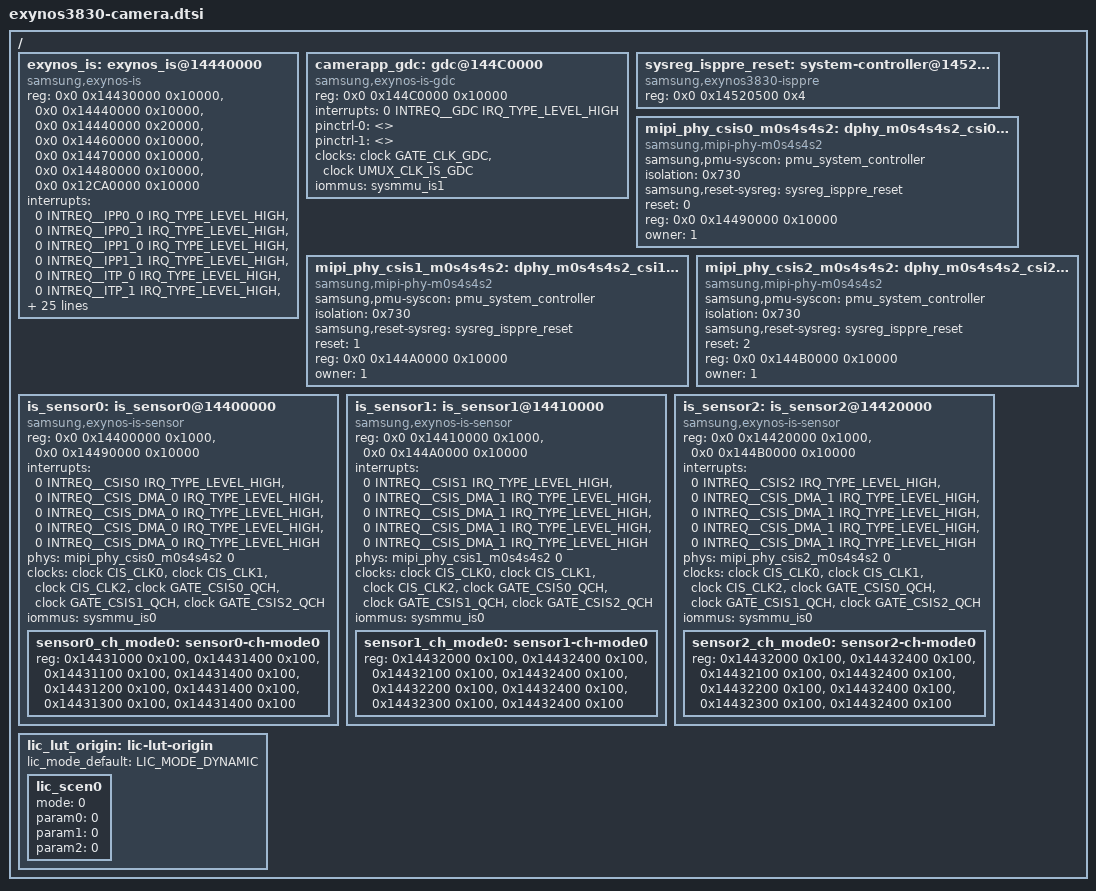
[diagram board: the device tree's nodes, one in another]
/*
 * SAMSUNG EXYNOS9630 SoC camera device tree source
 *
 * Copyright (c) 2019 Samsung Electronics Co., Ltd.
 *		http://www.samsung.com
 *
 * SAMSUNG EXYNOS9630 SoC camera device nodes are listed in this file.
 * EXYNOS9630 based board files can include this file and provide
 * values for board specfic bindings.
 *
 * This program is free software; you can redistribute it and/or modify
 * it under the terms of the GNU General Public License version 2 as
 * published by the Free Software Foundation.
 */

#include <dt-bindings/clock/exynos3830.h>
#include <dt-bindings/interrupt-controller/arm-gic.h>
#include <dt-bindings/interrupt-controller/exynos3830.h>
#include <dt-bindings/camera/exynos_is_dt.h>
#include "exynos3830-pinctrl.dtsi"
#include "exynos3830-sysmmu.dtsi"

/ {
	exynos_is: exynos_is@14440000 {
		compatible = "samsung,exynos-is";
		reg = <0x0 0x14430000 0x10000>, /* CSISX2  */
			<0x0 0x14440000 0x10000>, /* IPP0 */
			<0x0 0x14440000 0x20000>, /* IPP1 */
			<0x0 0x14460000 0x10000>, /* ITP0 */
			<0x0 0x14470000 0x10000>, /* MCSC_IS */
			<0x0 0x14480000 0x10000>, /* VRA */
			<0x0 0x12CA0000 0x10000>; /* MCSC_MFC */
		interrupts = <0 INTREQ__IPP0_0 IRQ_TYPE_LEVEL_HIGH>,	/* IPP0_0 */
			<0 INTREQ__IPP0_1 IRQ_TYPE_LEVEL_HIGH>,			/* IPP0_1 */
			<0 INTREQ__IPP1_0 IRQ_TYPE_LEVEL_HIGH>,			/* IPP1_0 */
			<0 INTREQ__IPP1_1 IRQ_TYPE_LEVEL_HIGH>,			/* IPP1_1 */
			<0 INTREQ__ITP_0 IRQ_TYPE_LEVEL_HIGH>,				/* ITP0_0 */
			<0 INTREQ__ITP_1 IRQ_TYPE_LEVEL_HIGH>,				/* ITP0_1 */
			<0 INTREQ__MCSC_IS IRQ_TYPE_LEVEL_HIGH>,			/* MCSC_IS */
			<0 INTREQ__VRA IRQ_TYPE_LEVEL_HIGH>,				/* VRA */
			<0 INTREQ__MCSC_MFC IRQ_TYPE_LEVEL_HIGH>;			/* MCSC_MFC */
		pinctrl-names = "default","release";
		pinctrl-0 = <>;
		pinctrl-1 = <>;
		clocks = <&clock IS_BUS>,
			<&clock IS_ITP>,
			<&clock IS_GDC>,
			<&clock IS_VRA>,
			<&clock MFCMSCL_MCSC>,

			<&clock UMUX_CLK_IS_BUS>,
			<&clock UMUX_CLK_IS_ITP>,
			<&clock UMUX_CLK_IS_VRA>,
			<&clock UMUX_CLK_IS_GDC>,

			<&clock GATE_CLK_ITP>,
			<&clock GATE_CLK_VRA>,
			<&clock GATE_CLK_GDC>,
			<&clock GATE_MCSC_QCH>,

			<&clock GATE_CSIS0_QCH>,
			<&clock GATE_CSIS1_QCH>,
			<&clock GATE_CSIS2_QCH>,

			<&clock GATE_DFTMUX_CMU_QCH_CLK_CIS0>,
			<&clock GATE_DFTMUX_CMU_QCH_CLK_CIS1>,
			<&clock GATE_DFTMUX_CMU_QCH_CLK_CIS2>,

			<&clock CIS_CLK0>,
			<&clock CIS_CLK1>,
			<&clock CIS_CLK2>;
		clock-names = "IS_BUS",
			"IS_ITP",
			"IS_GDC",
			"IS_VRA",
			"MFCMSCL_MCSC",

			"UMUX_CLK_IS_BUS",
			"UMUX_CLK_IS_ITP",
			"UMUX_CLK_IS_VRA",
			"UMUX_CLK_IS_GDC",

			"GATE_CLK_ITP",
			"GATE_CLK_VRA",
			"GATE_CLK_GDC",
			"GATE_MCSC_QCH",

			"GATE_CSIS0_QCH",
			"GATE_CSIS1_QCH",
			"GATE_CSIS2_QCH",

			"GATE_DFTMUX_CMU_QCH_CLK_CIS0",
			"GATE_DFTMUX_CMU_QCH_CLK_CIS1",
			"GATE_DFTMUX_CMU_QCH_CLK_CIS2",

			"CIS_CLK0",
			"CIS_CLK1",
			"CIS_CLK2";
		status = "ok";
		iommus = <&sysmmu_is0>, <&sysmmu_is1>, <&sysmmu_mfcmscl>;
		#cooling-cells = <2>; /* min followed by max */
		/* ewf-index = <EWF_CMU_BUSC>; */
		list-scen-bts = "camera_default";
		num_of_3aa = <2>;
		num_of_isp = <1>;
		num_of_mcsc = <2>;
		num_of_vra = <1>;
	};

	camerapp_gdc: gdc@144C0000 {
		compatible = "samsung,exynos-is-gdc";
		reg = <0x0 0x144C0000 0x10000>; /* GDC */
		interrupts = <0 INTREQ__GDC IRQ_TYPE_LEVEL_HIGH>; /* GDC */
		pinctrl-names = "default","release";
		pinctrl-0 = <>;
		pinctrl-1 = <>;
		clocks = <&clock GATE_CLK_GDC>,
				<&clock UMUX_CLK_IS_GDC>;
		clock-names = "gate",
					"gate2";
		status = "okay";
		iommus = <&sysmmu_is1>;
		#cooling-cells = <2>; /* min followed by max */
	};

	sysreg_isppre_reset: system-controller@14520500 {
		compatible = "samsung,exynos3830-isppre", "syscon";
		reg = <0x0 0x14520500 0x4>;
	};

	mipi_phy_csis0_m0s4s4s2: dphy_m0s4s4s2_csi0@14400000 {
		/* DPHY 2.5 Gbps 4lane */
		compatible = "samsung,mipi-phy-m0s4s4s2";
		samsung,pmu-syscon = <&pmu_system_controller>;
		isolation = <0x730>; /* PMU address offset */
		samsung,reset-sysreg = <&sysreg_isppre_reset>;
		reset = <0>; /* reset bit */
		reg = <0x0 0x14490000 0x10000>;
		owner = <1>; /* 0: DSI,  1: CSI */
		#phy-cells = <1>;
	};

	mipi_phy_csis1_m0s4s4s2: dphy_m0s4s4s2_csi1@14410000 {
		/* DPHY 2.5 Gbps 4lane */
		compatible = "samsung,mipi-phy-m0s4s4s2";
		samsung,pmu-syscon = <&pmu_system_controller>;
		isolation = <0x730>; /* PMU address offset */
		samsung,reset-sysreg = <&sysreg_isppre_reset>;
		reset = <1>; /* reset bit */
		reg = <0x0 0x144A0000 0x10000>;
		owner = <1>; /* 0: DSI,  1: CSI */
		#phy-cells = <1>;
	};

	mipi_phy_csis2_m0s4s4s2: dphy_m0s4s4s2_csi2@14420000 {
		/* DPHY 2.5 Gbps 4lane */
		compatible = "samsung,mipi-phy-m0s4s4s2";
		samsung,pmu-syscon = <&pmu_system_controller>;
		isolation = <0x730>; /* PMU address offset */
		samsung,reset-sysreg = <&sysreg_isppre_reset>;
		reset = <2>; /* reset bit */
		reg = <0x0 0x144B0000 0x10000>;
		owner = <1>; /* 0: DSI,  1: CSI */
		#phy-cells = <1>;
	};

	is_sensor0: is_sensor0@14400000 {
		/* CSIS0 */
		compatible = "samsung,exynos-is-sensor";
		#address-cells = <1>;
		#size-cells = <1>;
		reg = <0x0 0x14400000 0x1000>, /* MIPI-CSI0 */
			<0x0 0x14490000 0x10000>; /* PHY: m0s4s4s2 */
		reg-names = "csi", "phy";
		interrupts = <0 INTREQ__CSIS0 IRQ_TYPE_LEVEL_HIGH>, /*MIPI-CSI0 */
			<0 INTREQ__CSIS_DMA_0 IRQ_TYPE_LEVEL_HIGH>,
			<0 INTREQ__CSIS_DMA_0 IRQ_TYPE_LEVEL_HIGH>,
			<0 INTREQ__CSIS_DMA_0 IRQ_TYPE_LEVEL_HIGH>,
			<0 INTREQ__CSIS_DMA_0 IRQ_TYPE_LEVEL_HIGH>;
		interrupt-names = "csi",
			"mode0_VC0", "mode0_VC1", "mode0_VC2", "mode0_VC3";
		phys = <&mipi_phy_csis0_m0s4s4s2 0>;
		phy-names = "csis_dphy";
		clocks = <&clock CIS_CLK0>,
			<&clock CIS_CLK1>,
			<&clock CIS_CLK2>,

			<&clock GATE_CSIS0_QCH>,
			<&clock GATE_CSIS1_QCH>,
			<&clock GATE_CSIS2_QCH>;
		clock-names = "CIS_CLK0",
			"CIS_CLK1",
			"CIS_CLK2",

			"GATE_CSIS0_QCH",
			"GATE_CSIS1_QCH",
			"GATE_CSIS2_QCH";
		iommus = <&sysmmu_is0>;

		/* without PAF HW */
		sensor0_ch_mode0: sensor0-ch-mode0 {
			reg = <0x14431000 0x100>, /* DMA0 VC0 */
				<0x14431400 0x100>, /* DMA0 Common */
				<0x14431100 0x100>, /* DMA0 VC1 */
				<0x14431400 0x100>, /* DMA0 Common */
				<0x14431200 0x100>, /* DMA0 VC2 */
				<0x14431400 0x100>, /* DMA0 Common */
				<0x14431300 0x100>, /* DMA0 VC3 */
				<0x14431400 0x100>; /* DMA0 Common */
		};
	};

	is_sensor1: is_sensor1@14410000 {
		/* CSIS1 */
		compatible = "samsung,exynos-is-sensor";
		#address-cells = <1>;
		#size-cells = <1>;
		reg = <0x0 0x14410000 0x1000>, /* MIPI-CSI1 */
			<0x0 0x144A0000 0x10000>; /* PHY: m0s4s4s2 */
		reg-names = "csi", "phy";
		interrupts = <0 INTREQ__CSIS1 IRQ_TYPE_LEVEL_HIGH>, /* MIPI-CSI1 */
			<0 INTREQ__CSIS_DMA_1 IRQ_TYPE_LEVEL_HIGH>,
			<0 INTREQ__CSIS_DMA_1 IRQ_TYPE_LEVEL_HIGH>,
			<0 INTREQ__CSIS_DMA_1 IRQ_TYPE_LEVEL_HIGH>,
			<0 INTREQ__CSIS_DMA_1 IRQ_TYPE_LEVEL_HIGH>;
		interrupt-names = "csi",
			"mode0_VC0", "mode0_VC1", "mode0_VC2", "mode0_VC3";
		phys = <&mipi_phy_csis1_m0s4s4s2 0>;
		phy-names = "csis_dphy";
		clocks = <&clock CIS_CLK0>,
			<&clock CIS_CLK1>,
			<&clock CIS_CLK2>,

			<&clock GATE_CSIS0_QCH>,
			<&clock GATE_CSIS1_QCH>,
			<&clock GATE_CSIS2_QCH>;
		clock-names = "CIS_CLK0",
			"CIS_CLK1",
			"CIS_CLK2",

			"GATE_CSIS0_QCH",
			"GATE_CSIS1_QCH",
			"GATE_CSIS2_QCH";
		iommus = <&sysmmu_is0>;

		/* without PAF HW */
		sensor1_ch_mode0: sensor1-ch-mode0 {
			reg = <0x14432000 0x100>, /* DMA1 VC0 */
				<0x14432400 0x100>, /* DMA1 Common */
				<0x14432100 0x100>, /* DMA1 VC1 */
				<0x14432400 0x100>, /* DMA1 Common */
				<0x14432200 0x100>, /* DMA1 VC2 */
				<0x14432400 0x100>, /* DMA1 Common */
				<0x14432300 0x100>, /* DMA1 VC3 */
				<0x14432400 0x100>; /* DMA1 Common */
		};
	};

	is_sensor2: is_sensor2@14420000 {
		/* CSIS2 */
		compatible = "samsung,exynos-is-sensor";
		#address-cells = <1>;
		#size-cells = <1>;
		reg = <0x0 0x14420000 0x1000>, /* MIPI-CSI2 */
			<0x0 0x144B0000 0x10000>; /* PHY: m0s4s4s2 */
		reg-names = "csi", "phy";
		interrupts = <0 INTREQ__CSIS2 IRQ_TYPE_LEVEL_HIGH>, /* MIPI-CSI2 */
			<0 INTREQ__CSIS_DMA_1 IRQ_TYPE_LEVEL_HIGH>,
			<0 INTREQ__CSIS_DMA_1 IRQ_TYPE_LEVEL_HIGH>,
			<0 INTREQ__CSIS_DMA_1 IRQ_TYPE_LEVEL_HIGH>,
			<0 INTREQ__CSIS_DMA_1 IRQ_TYPE_LEVEL_HIGH>;
		interrupt-names = "csi",
			"mode0_VC0", "mode0_VC1", "mode0_VC2", "mode0_VC3";
		phys = <&mipi_phy_csis2_m0s4s4s2 0>;
		phy-names = "csis_dphy";
		clocks = <&clock CIS_CLK0>,
			<&clock CIS_CLK1>,
			<&clock CIS_CLK2>,

			<&clock GATE_CSIS0_QCH>,
			<&clock GATE_CSIS1_QCH>,
			<&clock GATE_CSIS2_QCH>;
		clock-names = "CIS_CLK0",
			"CIS_CLK1",
			"CIS_CLK2",

			"GATE_CSIS0_QCH",
			"GATE_CSIS1_QCH",
			"GATE_CSIS2_QCH";
		iommus = <&sysmmu_is0>;

		/* without PAF HW */
		sensor2_ch_mode0: sensor2-ch-mode0 {
			reg = <0x14432000 0x100>, /* DMA1 VC0 */
				<0x14432400 0x100>, /* DMA1 Common */
				<0x14432100 0x100>, /* DMA1 VC1 */
				<0x14432400 0x100>, /* DMA1 Common */
				<0x14432200 0x100>, /* DMA1 VC2 */
				<0x14432400 0x100>, /* DMA1 Common */
				<0x14432300 0x100>, /* DMA1 VC3 */
				<0x14432400 0x100>; /* DMA1 Common */
		};
	};

	lic_lut_origin: lic-lut-origin {
		#define LIC_MODE_DYNAMIC	(0)
		#define LIC_MODE_STATIC		(1)
		#define LIC_PATH_OTF		(0)
		#define LIC_PATH_DMA		(1)

		lic_mode_default = <LIC_MODE_DYNAMIC>;

		/*
		 * When DYNAMIC mode is selected, param means enable limitation for DMA path.
		 * Example:
		 * @ mode = <LIC_MODE_DYNAMIC>;
		 * @ param0 = <LIC_PATH_OTF>;
		 * @ param1 = <LIC_PATH_DMA>;
		 * @ param2 = <LIC_PATH_OTF>;
		 *
		 * When STATIC mode is selected, param means buffer size for each context.
		 * Example:
		 * @ mode = <LIC_MODE_STAIC>;
		 * @ param0 = <3584>;
		 * @ param1 = <3583>;
		 * @ param2 = <1>;
		 *
		 * The lic_scen0 is not abailable. If the index of LUT is "0", the selection is skipped.
		 */
		lic_scen0 { /* Reserved */
			mode = <0>;
			param0 = <0>;
			param1 = <0>;
			param2 = <0>;
		};
	};
};
